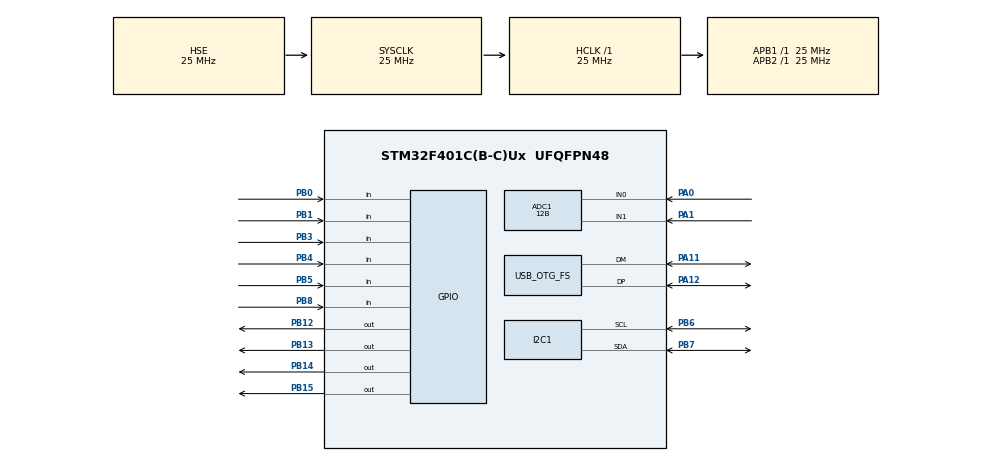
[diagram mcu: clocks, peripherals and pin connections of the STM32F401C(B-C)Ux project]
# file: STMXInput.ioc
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ADC1.Channel-1\#ChannelRegularConversion=ADC_CHANNEL_0
ADC1.ClockPrescaler=ADC_CLOCK_SYNC_PCLK_DIV8
ADC1.ContinuousConvMode=DISABLE
ADC1.NbrOfConversion=1
ADC1.NbrOfConversionFlag=1
ADC1.Rank-1\#ChannelRegularConversion=1
ADC1.Resolution=ADC_RESOLUTION_12B
ADC1.SamplingTime-1\#ChannelRegularConversion=ADC_SAMPLETIME_480CYCLES
ADC1.master=1
I2C1.I2C_Mode=I2C_Fast
Mcu.Family=STM32F4
Mcu.Name=STM32F401C(B-C)Ux
Mcu.Package=UFQFPN48
NVIC.OTG_FS_IRQn=true\:0\:0\:false\:false\:true\:false\:true
NVIC.PriorityGroup=NVIC_PRIORITYGROUP_4
PA0-WKUP.Signal=ADCx_IN0
PA1.Signal=ADCx_IN1
PA11.Mode=Device_Only
PA11.Signal=USB_OTG_FS_DM
PA12.Mode=Device_Only
PA12.Signal=USB_OTG_FS_DP
PB0.Signal=GPIO_Input
PB1.Signal=GPIO_Input
PB12.PinState=GPIO_PIN_SET
PB12.Signal=GPIO_Output
PB13.PinState=GPIO_PIN_SET
PB13.Signal=GPIO_Output
PB14.PinState=GPIO_PIN_SET
PB14.Signal=GPIO_Output
PB15.PinState=GPIO_PIN_SET
PB15.Signal=GPIO_Output
PB3.GPIO_PuPd=GPIO_PULLUP
PB3.Signal=GPIO_Input
PB4.GPIO_PuPd=GPIO_PULLUP
PB4.Signal=GPIO_Input
PB5.GPIO_PuPd=GPIO_PULLUP
PB5.Signal=GPIO_Input
PB6.Mode=I2C
PB6.Signal=I2C1_SCL
PB7.Mode=I2C
PB7.Signal=I2C1_SDA
PB8.GPIO_PuPd=GPIO_PULLUP
PB8.Signal=GPIO_Input
PH0\ -\ OSC_IN.Mode=HSE-External-Oscillator
PH0\ -\ OSC_IN.Signal=RCC_OSC_IN
PH1\ -\ OSC_OUT.Mode=HSE-External-Oscillator
PH1\ -\ OSC_OUT.Signal=RCC_OSC_OUT
ProjectManager.HeapSize=0x200
ProjectManager.StackSize=0x400
ProjectManager.TargetToolchain=STM32CubeIDE
RCC.48MHZClocksFreq_Value=48000000
RCC.AHBFreq_Value=25000000
RCC.APB1Freq_Value=25000000
RCC.APB1TimFreq_Value=25000000
RCC.APB2Freq_Value=25000000
RCC.APB2TimFreq_Value=25000000
RCC.CortexFreq_Value=25000000
RCC.HCLKFreq_Value=25000000
RCC.HSE_VALUE=25000000
RCC.HSI_VALUE=16000000
RCC.LSE_VALUE=32768
RCC.PLLM=15
RCC.PLLN=144
RCC.PLLQ=5
RCC.SYSCLKFreq_VALUE=25000000
RCC.SYSCLKSource=RCC_SYSCLKSOURCE_HSE
RCC.VCOOutputFreq_Value=240000000
SH.ADCx_IN0.0=ADC1_IN0,IN0
SH.ADCx_IN1.0=ADC1_IN1,IN1
USB_DEVICE.CLASS_NAME_FS=CUSTOM_HID
USB_DEVICE.MANUFACTURER_STRING=\u00A9Microsoft
USB_DEVICE.PID_CUSTOMHID_FS=0x028e
USB_DEVICE.PRODUCT_STRING_CUSTOMHID_FS=Controller
USB_DEVICE.VID=0x045e
USB_DEVICE.VirtualMode=CustomHid
USB_DEVICE.VirtualModeFS=Custom_Hid_FS
USB_OTG_FS.VirtualMode=Device_Only
VP_USB_DEVICE_VS_USB_DEVICE_CUSTOM_HID_FS.Mode=CUSTOM_HID_FS
board=custom

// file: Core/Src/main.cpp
/* USER CODE BEGIN Header */
/**
  ******************************************************************************
  * @file           : main.c
  * @brief          : Main program body
  ******************************************************************************
  * @attention
  *
  * <h2><center>&copy; Copyright (c) 2021 STMicroelectronics.
  * All rights reserved.</center></h2>
  *
  * This software component is licensed by ST under Ultimate Liberty license
  * SLA0044, the "License"; You may not use this file except in compliance with
  * the License. You may obtain a copy of the License at:
  *                             www.st.com/SLA0044
  *
  ******************************************************************************
  */
/* USER CODE END Header */
#include "main.h"
#include "Xbox.h"

//#define DEBUG

/* USER CODE BEGIN PD */

#define HIGH GPIO_PIN_SET
#define LOW GPIO_PIN_RESET

#define BUTTON_GPIO_GROUP GPIOB

#define BUTTON_REFRESH 100

#define ROT_GPIO_GROUP GPIOB

#define ROT1 18
#define ROT2 19

#define START_GPIO_GROUP GPIOA

#define START_BUTTON GPIO_PIN_8

#define PEDAL_GPIO_GROUP GPIOA

#define PEDAL_LOW 682.f //ADC value when pedal is released
#define PEDAL_HIGH 4095.f //ADC value when pedal is pressed
#define PEDAL_PRE 3413.f

//#define ROT_ENC_A_GPIO 29
//#define ROT_ENC_B_GPIO 30

#define AXIS_ZERO 0

#define one_rotation 13 // 360 degress

#define MAX_PEDAL_VALUE 255

/* USER CODE END PD */

ADC_HandleTypeDef hadc1;

I2C_HandleTypeDef hi2c1;

/* USER CODE BEGIN PV */

//pedal input pin gpio
const uint8_t pedal_pin[]={GPIO_PIN_1,GPIO_PIN_0};

//columns and rows gpio numbers for keypad
const uint16_t columns[]={GPIO_PIN_3,GPIO_PIN_4,GPIO_PIN_5,GPIO_PIN_8};

const uint16_t rows[]={GPIO_PIN_12,GPIO_PIN_13,GPIO_PIN_14,GPIO_PIN_15};

int rowCounter =0; // row counter
int columnCounter =0; // column counter
int captureColumn =0;
bool foundCol = false;

long start=0;
long stop=0;

float max_angle=180.f;

int position=0;
int lastPos=0;

long TimeOfLastDebounce=0;
float DelayofDebounce = 5;

//hw_timer_t * timer = NULL;

int keysState=0x0;

int PreviousCLK=0;
int PreviousDATA=0;

uint8_t curr_adc=0;

//#include "usbd_customhid.h"

//#include "usb_xinput.h"

/* USER CODE END PV */

void SystemClock_Config(void);
static void MX_GPIO_Init(void);
static void MX_ADC1_Init(void);
static void MX_I2C1_Init(void);
/* USER CODE BEGIN PFP */

uint8_t GET_USB_STATUS()
{
	if (hUsbDeviceFS.pClassData == NULL)
		  {
		    return (uint8_t)USBD_FAIL;
		  }

	return hUsbDeviceFS.dev_state;
}

bool IS_USB_SUSPEND()
{
	return GET_USB_STATUS()==USBD_STATE_SUSPENDED;
}

void switch_ADC(uint8_t adc)
{
	ADC_ChannelConfTypeDef sConfig = {0};

	sConfig.Channel = adc;
	  sConfig.Rank = 1;
	  sConfig.SamplingTime = ADC_SAMPLETIME_480CYCLES;
	  if (HAL_ADC_ConfigChannel(&hadc1, &sConfig) != HAL_OK)
	  {
	    Error_Handler();
	  }

	  curr_adc=adc;

}

void rotary_task()
{
	if((HAL_GetTick()- TimeOfLastDebounce) > DelayofDebounce)
	  {

	    if((PreviousCLK == 0)&&(PreviousDATA == 1))
	    {

	      if((HAL_GPIO_ReadPin(ROT_GPIO_GROUP,ROT1)==1)&&(HAL_GPIO_ReadPin(ROT_GPIO_GROUP,ROT2)==0))
	      {
	        position++;
	      }
	       if((HAL_GPIO_ReadPin(ROT_GPIO_GROUP,ROT1)==1)&&(HAL_GPIO_ReadPin(ROT_GPIO_GROUP,ROT2)==1))
	      {
	        position--;
	      }

	    }

	    if((PreviousCLK == 1)&&(PreviousDATA == 0))
	    {

	      if((HAL_GPIO_ReadPin(ROT_GPIO_GROUP,ROT1)==0)&&(HAL_GPIO_ReadPin(ROT_GPIO_GROUP,ROT2)==1))
	      {
	        position++;
	      }
	       if((HAL_GPIO_ReadPin(ROT_GPIO_GROUP,ROT1)==0)&&(HAL_GPIO_ReadPin(ROT_GPIO_GROUP,ROT2)==0))
	      {
	        position--;
	      }

	      // make_y_axis_querry(pos_to_angle(position));

	    }

	      if((PreviousCLK == 1)&&(PreviousDATA == 1))
	    {

	      if((HAL_GPIO_ReadPin(ROT_GPIO_GROUP,ROT1)==0)&&(HAL_GPIO_ReadPin(ROT_GPIO_GROUP,ROT2)==1))
	      {
	        position++;
	      }
	       if((HAL_GPIO_ReadPin(ROT_GPIO_GROUP,ROT1)==0)&&(HAL_GPIO_ReadPin(ROT_GPIO_GROUP,ROT2)==0))
	      {
	        position--;
	      }

	       //make_y_axis_querry(pos_to_angle(position));

	    }

	      if((PreviousCLK == 0)&&(PreviousDATA == 0))
	    {

	      if((HAL_GPIO_ReadPin(ROT_GPIO_GROUP,ROT1)==1)&&(HAL_GPIO_ReadPin(ROT_GPIO_GROUP,ROT2)==0))
	      {
	        position++;
	      }
	       if((HAL_GPIO_ReadPin(ROT_GPIO_GROUP,ROT1)==1)&&(HAL_GPIO_ReadPin(ROT_GPIO_GROUP,ROT2)==1))
	      {
	        position--;
	      }

	       //make_y_axis_querry(pos_to_angle(position));

	    }

	    PreviousCLK=HAL_GPIO_ReadPin(ROT_GPIO_GROUP,ROT1);
	    PreviousDATA=HAL_GPIO_ReadPin(ROT_GPIO_GROUP,ROT2);

	    TimeOfLastDebounce=HAL_GetTick();

	  }
}

void button_task()
{

for(int j =0; j < 4; j++){

HAL_GPIO_WritePin(BUTTON_GPIO_GROUP,rows[j],HIGH);

}

HAL_GPIO_WritePin(BUTTON_GPIO_GROUP,rows[rowCounter],LOW);

for(columnCounter=0;columnCounter<4;columnCounter++)
{

if(!HAL_GPIO_ReadPin(BUTTON_GPIO_GROUP,columns[columnCounter]))
{
keysState |= (1<<(4*rowCounter + columnCounter));
}
else
{
keysState &= ~(1<<(4*rowCounter + columnCounter));
}

}

rowCounter++;

if(rowCounter>=4)
{
  rowCounter=0;
}

}

void pedals(Xbox* _pad)
{

if(HAL_ADC_PollForConversion(&hadc1,10)== HAL_OK)
{

	uint16_t adc_read=0;

adc_read=HAL_ADC_GetValue(&hadc1);

//out=map(adc_read,PEDAL_LOW,PEDAL_HIGH,0,255);

_pad->setTrigger((XInputControl)(TRIGGER_LEFT+curr_adc),adc_read);

HAL_ADC_Stop(&hadc1);

if(curr_adc==0)
{
	curr_adc=1;
}
else
{
	curr_adc=0;
}

switch_ADC(curr_adc);

HAL_ADC_Start(&hadc1);

}

//memmove(msg+(sizeof(int)*2)+(i*sizeof(short)),(const void*)&out,sizeof(short));

}

bool read_button_state(int row , int column)
{
	return keysState ^= (1<<(4*row + column));
}

#define _DPAD_LEFT read_button_state(0,3)
#define _DPAD_DOWN read_button_state(1,3)
#define _DPAD_UP read_button_state(2,3)
#define _DPAD_RIGHT read_button_state(3,3)

#define A_BUTTON read_button_state(0,2)
#define B_BUTTON read_button_state(1,2)
#define X_BUTTON read_button_state(2,2)
#define Y_BUTTON read_button_state(3,2)

#define R2_BUTTON read_button_state(0,1)
#define _START_BUTTON read_button_state(1,1)
#define _BACK_BUTTON read_button_state(2,1)
#define L2_BUTTON read_button_state(3,1)

#define R3_BUTTON read_button_state(0,0)
#define L3_BUTTON read_button_state(3,0)

void decode_buttons(Xbox *pad)
{
	pad->setButton(DPAD_LEFT,_DPAD_LEFT);
	pad->setButton(DPAD_RIGHT,_DPAD_RIGHT);
	pad->setButton(DPAD_UP,_DPAD_UP);
	pad->setButton(DPAD_DOWN,_DPAD_DOWN);

	pad->setButton(BUTTON_A,A_BUTTON);
	pad->setButton(BUTTON_B,B_BUTTON);
	pad->setButton(BUTTON_X,X_BUTTON);
	pad->setButton(BUTTON_Y,Y_BUTTON);

	pad->setButton(BUTTON_RB,R2_BUTTON);
	pad->setButton(BUTTON_START,_START_BUTTON);
	pad->setButton(BUTTON_BACK,_BACK_BUTTON);
	pad->setButton(BUTTON_LB,L2_BUTTON);

	pad->setButton(BUTTON_R3,R3_BUTTON);
	pad->setButton(BUTTON_L3,L3_BUTTON);

}

/* USER CODE END PFP */

Xbox *gamepad;

int main(void)
{

  /* MCU Configuration--------------------------------------------------------*/

  /* Reset of all peripherals, Initializes the Flash interface and the Systick. */
  HAL_Init();

  /* Configure the system clock */
  SystemClock_Config();

  /* Initialize all configured peripherals */
  MX_GPIO_Init();
  MX_ADC1_Init();
  MX_I2C1_Init();
  //MX_USB_DEVICE_Init();
  gamepad=new Xbox();

  gamepad->setTriggerRange(PEDAL_LOW, PEDAL_HIGH);
  gamepad->setJoystickRange(-500,500);

  //uint8_t index=3;
  //uint8_t mask=(1<<4);

  //tx[index] |= mask;

  /* Infinite loop */
  /* USER CODE BEGIN WHILE */

HAL_GPIO_WritePin(GPIOC, GPIO_PIN_13,GPIO_PIN_RESET);

HAL_Delay(2000);

HAL_GPIO_WritePin(GPIOC, GPIO_PIN_13, GPIO_PIN_SET);

//bool but=false;

//gamepad->press(BUTTON_A);

HAL_ADC_Start(&hadc1);

  while (1)
  {

    /* USER CODE END WHILE */

	 // USBD_LL_Transmit(&hUsbDeviceFS,0x81,tx,20);
	  //gamepad->setButton(BUTTON_A,but);

	  //HAL_Delay(2000);

	  if(IS_USB_SUSPEND())
	  {
		  HAL_GPIO_WritePin(GPIOC, GPIO_PIN_13,GPIO_PIN_RESET);
	  }
	  else
	  {
		  HAL_GPIO_WritePin(GPIOC, GPIO_PIN_13, GPIO_PIN_SET);
	  }

	  while(!IS_USB_SUSPEND())
	  {

		  rotary_task();

		  //Gamepad.yAxis(pos_to_angle(position));
		  if(position!=lastPos)
		  {
			  gamepad->setJoystickX(JOY_LEFT, position);

		   lastPos=position;
		  }

		  if(stop-start>=BUTTON_REFRESH)
		  {

		  button_task();

		  decode_buttons(gamepad);

		  start=HAL_GetTick();
		  }

		  pedals(gamepad);

	  /*if(gamepad->getLEDPattern()!=0)
	  {
		  HAL_GPIO_WritePin(GPIOC, GPIO_PIN_13,GPIO_PIN_RESET);
	  }
	  else
	  {
		  HAL_GPIO_WritePin(GPIOC, GPIO_PIN_13,GPIO_PIN_SET);
	  }*/

	 // but=!but;

	  gamepad->send();

	  gamepad->receive();
	 // HAL_Delay(500);

    /* USER CODE BEGIN 3 */

	  stop=HAL_GetTick();

	  }

	//  HAL_Delay(10000);

  }
  /* USER CODE END 3 */
}

void SystemClock_Config(void)
{
  RCC_OscInitTypeDef RCC_OscInitStruct = {0};
  RCC_ClkInitTypeDef RCC_ClkInitStruct = {0};

  /** Configure the main internal regulator output voltage
  */
  __HAL_RCC_PWR_CLK_ENABLE();
  __HAL_PWR_VOLTAGESCALING_CONFIG(PWR_REGULATOR_VOLTAGE_SCALE2);
  /** Initializes the RCC Oscillators according to the specified parameters
  * in the RCC_OscInitTypeDef structure.
  */
  RCC_OscInitStruct.OscillatorType = RCC_OSCILLATORTYPE_HSE;
  RCC_OscInitStruct.HSEState = RCC_HSE_ON;
  RCC_OscInitStruct.PLL.PLLState = RCC_PLL_ON;
  RCC_OscInitStruct.PLL.PLLSource = RCC_PLLSOURCE_HSE;
  RCC_OscInitStruct.PLL.PLLM = 15;
  RCC_OscInitStruct.PLL.PLLN = 144;
  RCC_OscInitStruct.PLL.PLLP = RCC_PLLP_DIV2;
  RCC_OscInitStruct.PLL.PLLQ = 5;
  if (HAL_RCC_OscConfig(&RCC_OscInitStruct) != HAL_OK)
  {
    Error_Handler();
  }
  /** Initializes the CPU, AHB and APB buses clocks
  */
  RCC_ClkInitStruct.ClockType = RCC_CLOCKTYPE_HCLK|RCC_CLOCKTYPE_SYSCLK
                              |RCC_CLOCKTYPE_PCLK1|RCC_CLOCKTYPE_PCLK2;
  RCC_ClkInitStruct.SYSCLKSource = RCC_SYSCLKSOURCE_HSE;
  RCC_ClkInitStruct.AHBCLKDivider = RCC_SYSCLK_DIV1;
  RCC_ClkInitStruct.APB1CLKDivider = RCC_HCLK_DIV1;
  RCC_ClkInitStruct.APB2CLKDivider = RCC_HCLK_DIV1;

  if (HAL_RCC_ClockConfig(&RCC_ClkInitStruct, FLASH_LATENCY_0) != HAL_OK)
  {
    Error_Handler();
  }
}

static void MX_ADC1_Init(void)
{

  //ADC_ChannelConfTypeDef sConfig = {0};

  /** Configure the global features of the ADC (Clock, Resolution, Data Alignment and number of conversion)
  */
  hadc1.Instance = ADC1;
  hadc1.Init.ClockPrescaler = ADC_CLOCK_SYNC_PCLK_DIV8;
  hadc1.Init.Resolution = ADC_RESOLUTION_12B;
  hadc1.Init.ScanConvMode = DISABLE;
  hadc1.Init.ContinuousConvMode = DISABLE;
  hadc1.Init.DiscontinuousConvMode = DISABLE;
  hadc1.Init.ExternalTrigConvEdge = ADC_EXTERNALTRIGCONVEDGE_NONE;
  hadc1.Init.ExternalTrigConv = ADC_SOFTWARE_START;
  hadc1.Init.DataAlign = ADC_DATAALIGN_RIGHT;
  hadc1.Init.NbrOfConversion = 1;
  hadc1.Init.DMAContinuousRequests = DISABLE;
  hadc1.Init.EOCSelection = ADC_EOC_SINGLE_CONV;
  if (HAL_ADC_Init(&hadc1) != HAL_OK)
  {
    Error_Handler();
  }
  /** Configure for the selected ADC regular channel its corresponding rank in the sequencer and its sample time.
  */
  /*sConfig.Channel = ADC_CHANNEL_0;
  sConfig.Rank = 1;
  sConfig.SamplingTime = ADC_SAMPLETIME_480CYCLES;
  if (HAL_ADC_ConfigChannel(&hadc1, &sConfig) != HAL_OK)
  {
    Error_Handler();
  }*/

  switch_ADC(curr_adc);

}

static void MX_I2C1_Init(void)
{

  hi2c1.Instance = I2C1;
  hi2c1.Init.ClockSpeed = 400000;
  hi2c1.Init.DutyCycle = I2C_DUTYCYCLE_2;
  hi2c1.Init.OwnAddress1 = 0;
  hi2c1.Init.AddressingMode = I2C_ADDRESSINGMODE_7BIT;
  hi2c1.Init.DualAddressMode = I2C_DUALADDRESS_DISABLE;
  hi2c1.Init.OwnAddress2 = 0;
  hi2c1.Init.GeneralCallMode = I2C_GENERALCALL_DISABLE;
  hi2c1.Init.NoStretchMode = I2C_NOSTRETCH_DISABLE;
  if (HAL_I2C_Init(&hi2c1) != HAL_OK)
  {
    Error_Handler();
  }

}

static void MX_GPIO_Init(void)
{
  GPIO_InitTypeDef GPIO_InitStruct = {0};

  /* GPIO Ports Clock Enable */
  __HAL_RCC_GPIOH_CLK_ENABLE();
  __HAL_RCC_GPIOA_CLK_ENABLE();
  __HAL_RCC_GPIOB_CLK_ENABLE();

  /*Configure GPIO pin Output Level */
  HAL_GPIO_WritePin(GPIOB, GPIO_PIN_12|GPIO_PIN_13|GPIO_PIN_14|GPIO_PIN_15, GPIO_PIN_SET);

  /*Configure GPIO pins : PB0 PB1 */
  GPIO_InitStruct.Pin = GPIO_PIN_0|GPIO_PIN_1;
  GPIO_InitStruct.Mode = GPIO_MODE_INPUT;
  GPIO_InitStruct.Pull = GPIO_NOPULL;
  HAL_GPIO_Init(GPIOB, &GPIO_InitStruct);

  /*Configure GPIO pins : PB12 PB13 PB14 PB15 */
  GPIO_InitStruct.Pin = GPIO_PIN_12|GPIO_PIN_13|GPIO_PIN_14|GPIO_PIN_15;
  GPIO_InitStruct.Mode = GPIO_MODE_OUTPUT_PP;
  GPIO_InitStruct.Pull = GPIO_NOPULL;
  GPIO_InitStruct.Speed = GPIO_SPEED_FREQ_LOW;
  HAL_GPIO_Init(GPIOB, &GPIO_InitStruct);

  /*Configure GPIO pins : PB3 PB4 PB5 PB8 */
  GPIO_InitStruct.Pin = GPIO_PIN_3|GPIO_PIN_4|GPIO_PIN_5|GPIO_PIN_8;
  GPIO_InitStruct.Mode = GPIO_MODE_INPUT;
  GPIO_InitStruct.Pull = GPIO_PULLUP;
  HAL_GPIO_Init(GPIOB, &GPIO_InitStruct);

  /*Configure GPIO pins : PA8 */
    GPIO_InitStruct.Pin = GPIO_PIN_8;
    GPIO_InitStruct.Mode = GPIO_MODE_INPUT;
    GPIO_InitStruct.Pull = GPIO_PULLUP;
    HAL_GPIO_Init(GPIOA, &GPIO_InitStruct);

}

void Error_Handler(void)
{
  __disable_irq();
  while (1)
  {
  }
}

/************************ (C) COPYRIGHT STMicroelectronics *****END OF FILE****/
